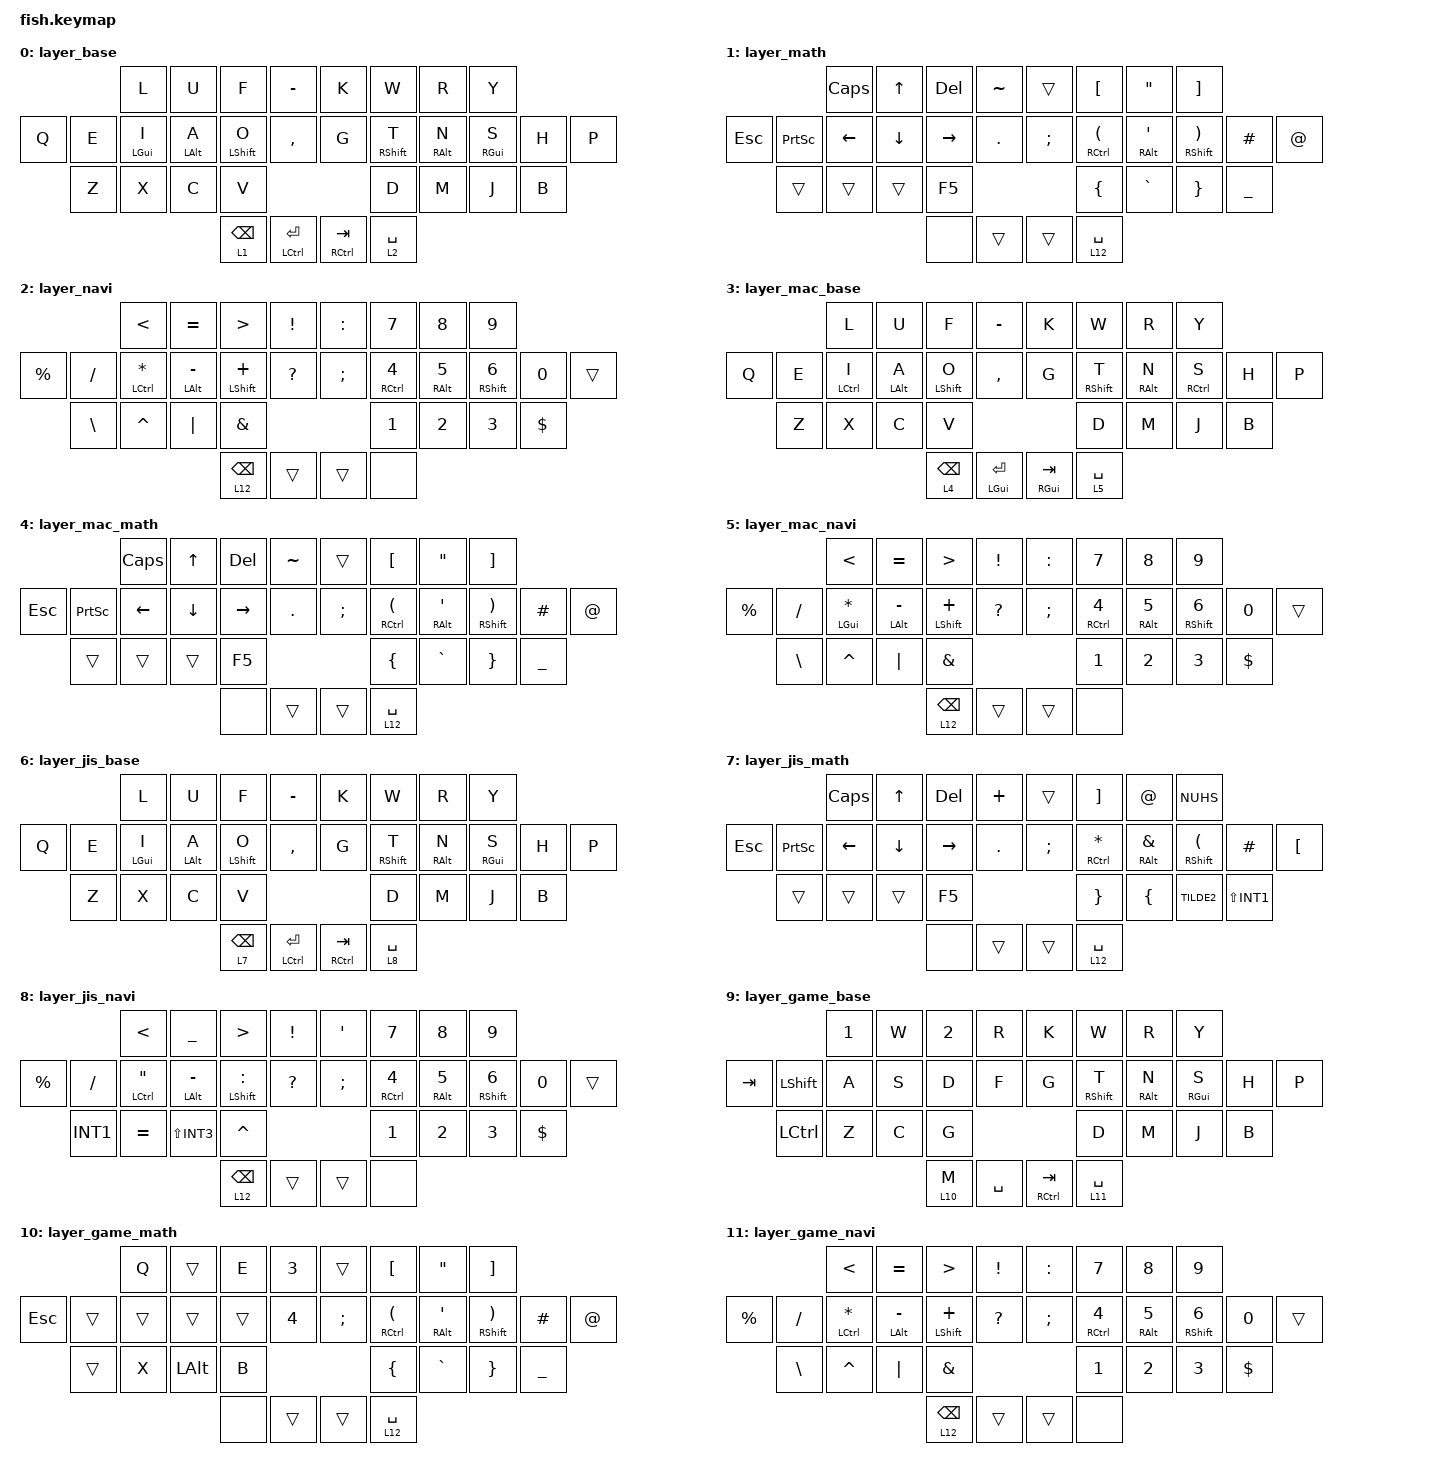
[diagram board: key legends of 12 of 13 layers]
// デフォルトキーマップ（大西配列、Win優先、ANSI方式）
// キーマップを更新する方法は https://o24.works/fish/guide を参照
// 視覚的に編集するには https://o24.works/fish/editor を参照


// 定義を呼んでくる
#include <behaviors.dtsi>
#include <dt-bindings/zmk/keys.h>
#include <dt-bindings/zmk/mouse.h>
#include <dt-bindings/zmk/bt.h>
#include <dt-bindings/zmk/outputs.h>
#include <dt-bindings/zmk/pointing.h>


// 特殊入力の挙動を調整できる

&mt {
    flavor = "tap-preferred";
    tapping-term-ms = <225>;
    quick-tap-ms = <200>;
    require-prior-idle-ms = <150>;
};

&lt {
    flavor = "balanced";
    tapping-term-ms = <175>;
    quick-tap-ms = <200>;
};

&sk {
};

&sl {
};

&caps_word {
};

&key_repeat {
};


/ {
    // 独自の入力を定義できる（上級者向け）

    behaviors {
    };

    macros {
        nn_macro: nn_macro {
            compatible = "zmk,behavior-macro";
            #binding-cells = <0>;
            bindings = <
                &kp N
                &kp N
            >;
        };
    };

    conditional_layers {
    };


    // 複数キーの同時押しに特別の入力を設定できる
    // キー番号早見表：
    //       0  1  2  3     4  5  6  7
    // 8  9 10 11 12 13    14 15 16 17 18 19
    //   20 21 22 23          24 25 26 27
    //            28 29    30 31

    combos {
        compatible = "zmk,combos";
        timeout-ms = <100>;
        require-prior-idle-ms = <150>;

        combo_lang2 {
            key-positions = <11 12>;
            bindings = <&kp LANG2>;
        };

        combo_lang1 {
            key-positions = <15 16>;
            bindings = <&kp LANG1>;
        };
        
        combo_nn {
            key-positions = <16 17>;
            bindings = <&nn_macro>;
        };

        combo_reset_L {
            key-positions = <3 8 13>;
            bindings = <&bootloader>;
        };

        combo_reset_R {
            key-positions = <4 14 19>;
            bindings = <&bootloader>;
        };

        combo_studio_unlock {
            key-positions = <20 21 22 23>;
            bindings = <&studio_unlock>;
        };
    };
    

    // キーに入力を割り当てる
    // 型（&...）は https://zmk.dev/docs/behaviors/... を参照
    // キーコードは https://zmk.dev/docs/codes/... を参照

    keymap {
        compatible = "zmk,keymap";

        layer_base {
            bindings = <
                        &kp L       &kp U       &kp F       &kp MINUS           &kp K       &kp W       &kp R       &kp Y       
&kp Q       &kp E       &mt LGUI I  &mt LALT A  &mt LSHFT O &kp COMMA           &kp G       &mt RSHFT T &mt RALT N  &mt RGUI S  &kp H       &kp P       
            &kp Z       &kp X       &kp C       &kp V                                       &kp D       &kp M       &kp J       &kp B       
                                                &lt 1 BSPC  &mt LCTRL RET       &mt RCTRL TAB &lt 2 SPACE 
            >;
        };

        layer_math {
            bindings = <
                        &kp CAPS    &kp UP      &kp DEL     &kp TILDE           &trans      &kp LBKT    &kp DQT     &kp RBKT      
&kp ESC     &kp PSCRN   &kp LEFT    &kp DOWN    &kp RIGHT   &kp DOT             &kp SEMI    &mt RCTRL LPAR &mt RALT SQT &mt RSHFT RPAR &kp HASH &kp AT 
            &trans      &trans      &trans      &kp F5                                      &kp LBRC    &kp GRAVE   &kp RBRC   &kp UNDER    
                                                &none       &trans              &trans      &lt 12 SPACE 
            >;
        };

        layer_navi {
            bindings = <
                        &kp LT      &kp EQUAL   &kp GT      &kp EXCL            &kp COLON   &kp N7      &kp N8      &kp N9      
&kp PRCNT   &kp FSLH    &mt LCTRL STAR &mt LALT MINUS &mt LSHFT PLUS &kp QMARK  &kp SEMI    &mt RCTRL N4 &mt RALT N5  &mt RSHFT N6 &kp N0   &trans
            &kp BSLH    &kp CARET   &kp PIPE    &kp AMPS                                    &kp N1      &kp N2      &kp N3      &kp DLLR
                                                &lt 12 BSPC  &trans              &trans      &none       
            >;
        };

        layer_mac_base {
            bindings = <
                        &kp L       &kp U       &kp F       &kp MINUS           &kp K       &kp W       &kp R       &kp Y
&kp Q       &kp E       &mt LCTRL I &mt LALT A  &mt LSHFT O &kp COMMA           &kp G       &mt RSHFT T &mt RALT N  &mt RCTRL S &kp H       &kp P
            &kp Z       &kp X       &kp C       &kp V                                       &kp D       &kp M       &kp J       &kp B
                                                &lt 4 BSPC  &mt LGUI RET        &mt RGUI TAB &lt 5 SPACE
            >;
        };

        layer_mac_math {
            bindings = <
                        &kp CAPS    &kp UP      &kp DEL     &kp TILDE           &trans      &kp LBKT    &kp DQT     &kp RBKT
&kp ESC     &kp PSCRN   &kp LEFT    &kp DOWN    &kp RIGHT   &kp DOT             &kp SEMI    &mt RCTRL LPAR &mt RALT SQT &mt RSHFT RPAR &kp HASH &kp AT
            &trans      &trans      &trans      &kp F5                                      &kp LBRC    &kp GRAVE   &kp RBRC   &kp UNDER
                                                &none       &trans              &trans      &lt 12 SPACE
            >;
        };

        layer_mac_navi {
            bindings = <
                        &kp LT      &kp EQUAL   &kp GT      &kp EXCL            &kp COLON   &kp N7      &kp N8      &kp N9
&kp PRCNT   &kp FSLH    &mt LGUI STAR &mt LALT MINUS &mt LSHFT PLUS &kp QMARK   &kp SEMI    &mt RCTRL N4 &mt RALT N5  &mt RSHFT N6 &kp N0   &trans
            &kp BSLH    &kp CARET   &kp PIPE    &kp AMPS                                    &kp N1      &kp N2      &kp N3      &kp DLLR
                                                &lt 12 BSPC &trans              &trans      &none
            >;
        };

        layer_jis_base {
            bindings = <
                        &kp L       &kp U       &kp F       &kp MINUS           &kp K       &kp W       &kp R       &kp Y
&kp Q       &kp E       &mt LGUI I  &mt LALT A  &mt LSHFT O &kp COMMA           &kp G       &mt RSHFT T &mt RALT N  &mt RGUI S  &kp H       &kp P
            &kp Z       &kp X       &kp C       &kp V                                       &kp D       &kp M       &kp J       &kp B
                                                &lt 7 BSPC  &mt LCTRL RET       &mt RCTRL TAB &lt 8 SPACE
            >;
        };

        layer_jis_math {
            bindings = <
                        &kp CAPS    &kp UP      &kp DEL     &kp PLUS            &trans      &kp RBKT    &kp AT      &kp NUHS
&kp ESC     &kp PSCRN   &kp LEFT    &kp DOWN    &kp RIGHT   &kp DOT             &kp SEMI    &mt RCTRL STAR &mt RALT AMPS &mt RSHFT LPAR &kp HASH &kp LBKT
            &trans      &trans      &trans      &kp F5                                     &kp RBRC    &kp LBRC    &kp TILDE2  &kp LS(INT1)
                                                &none       &trans              &trans      &lt 12 SPACE
            >;
        };

        layer_jis_navi {
            bindings = <
                        &kp LT      &kp UNDER   &kp GT      &kp EXCL            &kp SQT    &kp N7      &kp N8      &kp N9
&kp PRCNT   &kp FSLH    &mt LCTRL DQT &mt LALT MINUS &mt LSHFT COLON &kp QMARK  &kp SEMI   &mt RCTRL N4 &mt RALT N5  &mt RSHFT N6 &kp N0   &trans
            &kp INT1    &kp EQUAL   &kp LS(INT3) &kp CARET                                 &kp N1      &kp N2      &kp N3      &kp DLLR
                                                &lt 12 BSPC &trans              &trans      &none
            >;
        };

        layer_game_base {
            bindings = <
                        &kp N1      &kp W       &kp N2      &kp R               &kp K       &kp W       &kp R       &kp Y       
&kp TAB     &kp LSHFT   &kp A       &kp S       &kp D       &kp F               &kp G       &mt RSHFT T &mt RALT N  &mt RGUI S  &kp H       &kp P       
            &kp LCTRL   &kp Z       &kp C       &kp G                                       &kp D       &kp M       &kp J       &kp B       
                                                &lt 10 M    &kp SPACE           &mt RCTRL TAB &lt 11 SPACE 
            >;
        };

        layer_game_math {
            bindings = <
                        &kp Q       &trans      &kp E       &kp N3              &trans      &kp LBKT    &kp DQT     &kp RBKT      
&kp ESC     &trans      &trans      &trans      &trans      &kp N4              &kp SEMI    &mt RCTRL LPAR &mt RALT SQT &mt RSHFT RPAR &kp HASH &kp AT
            &trans      &kp X       &kp LALT    &kp B                                       &kp LBRC    &kp GRAVE   &kp RBRC   &kp UNDER  
                                                &none       &trans              &trans      &lt 12 SPACE 
            >;
        };

        layer_game_navi {
            bindings = <
                        &kp LT      &kp EQUAL   &kp GT      &kp EXCL            &kp COLON   &kp N7      &kp N8      &kp N9      
&kp PRCNT   &kp FSLH    &mt LCTRL STAR &mt LALT MINUS &mt LSHFT PLUS &kp QMARK  &kp SEMI    &mt RCTRL N4 &mt RALT N5  &mt RSHFT N6 &kp N0   &trans
            &kp BSLH    &kp CARET   &kp PIPE    &kp AMPS                                    &kp N1      &kp N2      &kp N3      &kp DLLR
                                                &lt 12 BSPC  &trans              &trans      &none       
            >;
        };

        layer_system {
            bindings = <
                        &bt BT_SEL 4 &bt BT_CLR &bt BT_CLR_ALL &out OUT_TOG     &to 0       &to 3       &to 6       &to 9   
&kp F1      &bt BT_SEL 0 &bt BT_SEL 1 &bt BT_SEL 2 &bt BT_SEL 3 &kp F6          &kp F7      &kp HOME    &kp END     &kp PG_DN   &kp K_APP   &kp F12     
            &kp F2      &kp F3      &kp F4      &kp F5                                      &kp F8      &kp F9      &kp F10     &kp F11     
                                                &none       &none               &none       &none       
            >;
        };
    };
};
